# ATtiny44A register map
Vendor: Atmel; File version: 1.0
CPU: other r0p0, little endian, no MPU, no FPU, 4 interrupt priority bits
Registers are 8-bit, read-write, reset 0x0 unless marked. A register's access mark holds for its fields unless they carry their own. Offsets are from the block's base; [hi:lo] are bit positions; {n}, {i} and the like mark numbered series.

## CPU — CPU Registers
Base 0x00800020
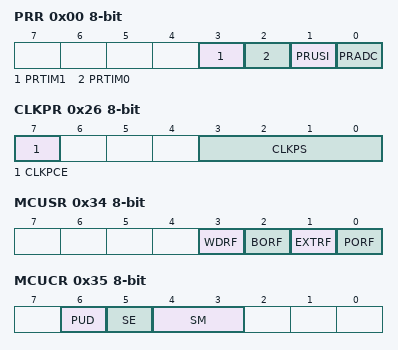
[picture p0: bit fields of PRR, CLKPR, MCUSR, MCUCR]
0x00 PRR — Power Reduction Register
  [3] PRTIM1 — Power Reduction Timer/Counter1
  [2] PRTIM0 — Power Reduction Timer/Counter0
  [1] PRUSI — Power Reduction USI
  [0] PRADC — Power Reduction ADC
{0x13+i} GPIOR{i} (i=0..2) — General Purpose I/O Register {i}
0x26 CLKPR — Clock Prescale Register
  [7] CLKPCE — Clock Prescaler Change Enable
  [3:0] CLKPS — Clock Prescaler Select Bits
    0=1; 1=2; 2=4; 3=8; 4=16; 5=32; 6=64; 7=128; 8=256
0x31 OSCCAL — Oscillator Calibration Value (read-only for debugger)
  [7:0] OSCCAL — Oscillator Calibration
0x34 MCUSR — MCU Status Register
  [3] WDRF — Watchdog Reset Flag
  [2] BORF — Brown-out Reset Flag
  [1] EXTRF — External Reset Flag
  [0] PORF — Power-on reset flag
0x35 MCUCR — MCU Control Register
  [6] PUD — Pull-up Disable
  [5] SE — Sleep Enable
  [4:3] SM — Sleep Mode Select Bits
    0=IDLE; 1=ADC (ADC Noise Reduction (If Available)); 2=PDOWN (Power Down); 3=STDBY (Standby)
0x3D SP 16-bit (reset mask 0xFF) — Stack Pointer
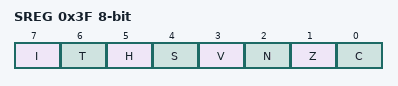
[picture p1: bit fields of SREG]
0x3F SREG — Status Register
  [7] I — Global Interrupt Enable
  [6] T — Bit Copy Storage
  [5] H — Half Carry Flag
  [4] S — Sign Bit
  [3] V — Two's Complement Overflow Flag
  [2] N — Negative Flag
  [1] Z — Zero Flag
  [0] C — Carry Flag

## EEPROM
Base 0x0080003C
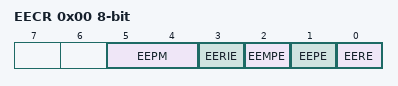
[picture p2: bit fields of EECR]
0x00 EECR — EEPROM Control Register
  [5:4] EEPM — EEPROM Programming Mode Bits
    0=ERASE_AND_WRITE_IN_ONE_OPERATION; 1=ERASE_ONLY; 2=WRITE_ONLY
  [3] EERIE — EEPROM Ready Interrupt Enable
  [2] EEMPE — EEPROM Master Write Enable
  [1] EEPE — EEPROM Write Enable
  [0] EERE — EEPROM Read Enable
0x01 EEDR — EEPROM Data Register
0x02 EEAR 16-bit (reset mask 0xFF) — EEPROM Address Register Bytes

## EXINT — External Interrupts
Base 0x00800032
0x00 PCMSK0 — Pin Change Enable Mask 0
0x0E PCMSK1 — Pin Change Enable Mask 1
0x23 MCUCR — MCU Control Register
  [1:0] ISC0 — Interrupt Sense Control 0
    0=LOW_LEVEL_OF_INTX; 1=ANY_LOGICAL_CHANGE_OF_INTX; 2=FALLING_EDGE_OF_INTX; 3=RISING_EDGE_OF_INTX
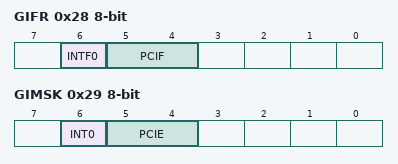
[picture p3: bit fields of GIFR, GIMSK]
0x28 GIFR — General Interrupt Flag register (read-only for debugger)
  [6] INTF0 — External Interrupt Flag 0
  [5:4] PCIF — Pin Change Interrupt Flags
0x29 GIMSK — General Interrupt Mask Register
  [6] INT0 — External Interrupt Request 0 Enable
  [5:4] PCIE — Pin Change Interrupt Enables

## PORTA — I/O Port
Base 0x00800039
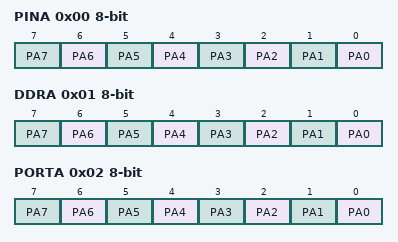
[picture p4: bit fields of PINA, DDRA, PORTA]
0x00 PINA — Port A Input Pins (read-only for debugger)
  [n] PA{n} (n=0..7) — Pin A{n}
0x01 DDRA — Port A Data Direction Register
  [n] PA{n} (n=0..7) — Pin A{n}
0x02 PORTA — Port A Data Register
  [n] PA{n} (n=0..7) — Pin A{n}

## PORTB — I/O Port
Base 0x00800036
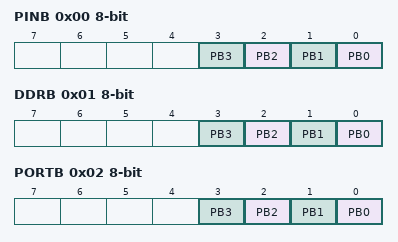
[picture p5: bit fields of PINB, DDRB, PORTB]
0x00 PINB — Input Pins, Port B (read-only for debugger)
  [n] PB{n} (n=0..3) — Pin B{n}
0x01 DDRB — Data Direction Register, Port B
  [n] PB{n} (n=0..3) — Pin B{n}
0x02 PORTB — Data Register, Port B
  [n] PB{n} (n=0..3) — Pin B{n}

## TC0 — Timer/Counter, 8-bit
Base 0x00800043
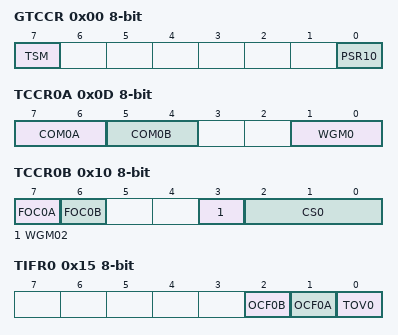
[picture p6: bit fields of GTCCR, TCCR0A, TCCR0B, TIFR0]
0x00 GTCCR — General Timer/Counter Control Register
  [7] TSM — Timer/Counter Synchronization Mode
  [0] PSR10 — Prescaler Reset Timer/CounterN
0x0D TCCR0A — Timer/Counter Control Register A
  [7:6] COM0A — Compare Match Output A Mode bits
  [5:4] COM0B — Compare Match Output B Mode bits
  [1:0] WGM0 — Waveform Generation Mode bits
0x0F TCNT0 — Timer/Counter0
0x10 TCCR0B — Timer/Counter Control Register B
  [7] FOC0A — Force Output Compare A
  [6] FOC0B — Force Output Compare B
  [3] WGM02 — Waveform Generation Mode bit 2
  [2:0] CS0 — Clock Select bits
    0=NO_CLOCK_SOURCE_STOPPED; 1=RUNNING_NO_PRESCALING; 2=RUNNING_CLK_8; 3=RUNNING_CLK_64; 4=RUNNING_CLK_256; 5=RUNNING_CLK_1024; 6=RUNNING_EXTCLK_TN_FALLING_EDGE; 7=RUNNING_EXTCLK_TN_RISING_EDGE
0x13 OCR0A — Timer/Counter0 Output Compare Register A
0x15 TIFR0 — Timer/Counter0 Interrupt Flag Register (read-only for debugger)
  [2] OCF0B — Timer/Counter0 Output Compare Flag B
  [1] OCF0A — Timer/Counter0 Output Compare Flag A
  [0] TOV0 — Timer/Counter0 Overflow Flag
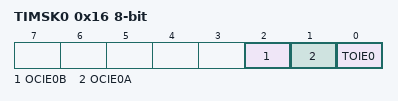
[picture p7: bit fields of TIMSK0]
0x16 TIMSK0 — Timer/Counter Interrupt Mask Register
  [2] OCIE0B — Timer/Counter0 Output Compare Match B Interrupt Enable
  [1] OCIE0A — Timer/Counter0 Output Compare Match A Interrupt Enable
  [0] TOIE0 — Timer/Counter0 Overflow Interrupt Enable
0x19 OCR0B — Timer/Counter0 Output Compare Register B

## TC1 — Timer/Counter, 16-bit
Base 0x0080002B
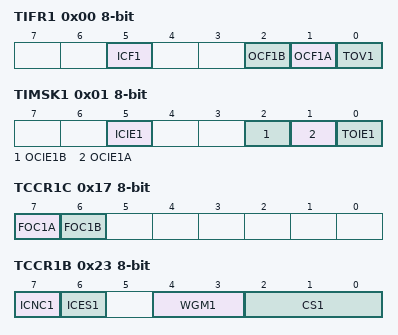
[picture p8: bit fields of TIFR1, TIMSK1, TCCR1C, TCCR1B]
0x00 TIFR1 — Timer/Counter Interrupt Flag register (read-only for debugger)
  [5] ICF1 — Timer/Counter1 Input Capture Flag
  [2] OCF1B — Timer/Counter1 Output Compare B Match Flag
  [1] OCF1A — Timer/Counter1 Output Compare A Match Flag
  [0] TOV1 — Timer/Counter1 Overflow Flag
0x01 TIMSK1 — Timer/Counter1 Interrupt Mask Register
  [5] ICIE1 — Timer/Counter1 Input Capture Interrupt Enable
  [2] OCIE1B — Timer/Counter1 Output Compare B Match Interrupt Enable
  [1] OCIE1A — Timer/Counter1 Output Compare A Match Interrupt Enable
  [0] TOIE1 — Timer/Counter1 Overflow Interrupt Enable
0x17 TCCR1C — Timer/Counter1 Control Register C (write-only for debugger)
  [7] FOC1A — Force Output Compare for Channel A
  [6] FOC1B — Force Output Compare for Channel B
0x19 ICR1 16-bit (reset mask 0xFF) — Timer/Counter1 Input Capture Register Bytes
0x1D OCR1B 16-bit (reset mask 0xFF) — Timer/Counter1 Output Compare Register B Bytes
0x1F OCR1A 16-bit (reset mask 0xFF) — Timer/Counter1 Output Compare Register A Bytes
0x21 TCNT1 16-bit (reset mask 0xFF) — Timer/Counter1 Bytes
0x23 TCCR1B — Timer/Counter1 Control Register B
  [7] ICNC1 — Input Capture 1 Noise Canceler
  [6] ICES1 — Input Capture 1 Edge Select
  [4:3] WGM1 — Waveform Generation Mode Bits
  [2:0] CS1 — Clock Select1 bits
    0=NO_CLOCK_SOURCE_STOPPED; 1=RUNNING_NO_PRESCALING; 2=RUNNING_CLK_8; 3=RUNNING_CLK_64; 4=RUNNING_CLK_256; 5=RUNNING_CLK_1024; 6=RUNNING_EXTCLK_TN_FALLING_EDGE; 7=RUNNING_EXTCLK_TN_RISING_EDGE
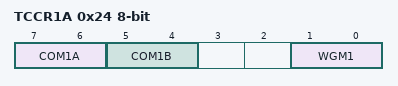
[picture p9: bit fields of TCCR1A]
0x24 TCCR1A — Timer/Counter1 Control Register A
  [7:6] COM1A — Compare Output Mode 1A, bits
  [5:4] COM1B — Compare Output Mode 1B, bits
  [1:0] WGM1 — Pulse Width Modulator Select Bits

## USI — Universal Serial Interface
Base 0x0080002D
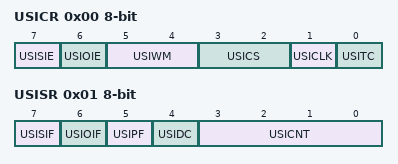
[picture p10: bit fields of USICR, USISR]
0x00 USICR — USI Control Register
  [7] USISIE — Start Condition Interrupt Enable
  [6] USIOIE — Counter Overflow Interrupt Enable
  [5:4] USIWM — USI Wire Mode Bits
    0=NORMAL_OPERATION; 1=THREE_WIRE_MODE; 2=TWO_WIRE_MODE; 3=TWO_WIRE_MODE_HELD_LOW
  [3:2] USICS — USI Clock Source Select Bits
  [1] USICLK — Clock Strobe
  [0] USITC — Toggle Clock Port Pin
0x01 USISR — USI Status Register (read-only for debugger)
  [7] USISIF — Start Condition Interrupt Flag
  [6] USIOIF — Counter Overflow Interrupt Flag
  [5] USIPF — Stop Condition Flag
  [4] USIDC — Data Output Collision
  [3:0] USICNT — USI Counter Value Bits
0x02 USIDR — USI Data Register
0x03 USIBR — USI Buffer Register (read-only for debugger)

## WDT — Watchdog Timer
Base 0x00800041
0x00 WDTCSR — Watchdog Timer Control Register (read-only for debugger)
  [7] WDIF — Watchdog Timeout Interrupt Flag
  [6] WDIE — Watchdog Timeout Interrupt Enable
  [4] WDCE — Watchdog Change Enable
  [3] WDE — Watch Dog Enable
  [5:0] WDP — Watchdog Timer Prescaler Bits
    0=OSCILLATOR_CYCLES_2K; 1=OSCILLATOR_CYCLES_4K; 2=OSCILLATOR_CYCLES_8K; 3=OSCILLATOR_CYCLES_16K; 4=OSCILLATOR_CYCLES_32K; 5=OSCILLATOR_CYCLES_64K; 6=OSCILLATOR_CYCLES_128K; 7=OSCILLATOR_CYCLES_256K
